# USB3_PHY_RX register map
Vendor: Texas Instruments
Peripheral module from a debugger description file (folder am571x).
Registers are 32-bit, access per field, reset 0x0 unless marked. A register's access mark holds for its fields unless they carry their own. Offsets are as the file gives them; lines under a group give offsets from that group; [hi:lo] are bit positions; {n}, {i} and the like mark numbered series; 'fields as' and 'values as' point back to an identical list; <NAME> marks a mode.

## USB3_PHY_RX
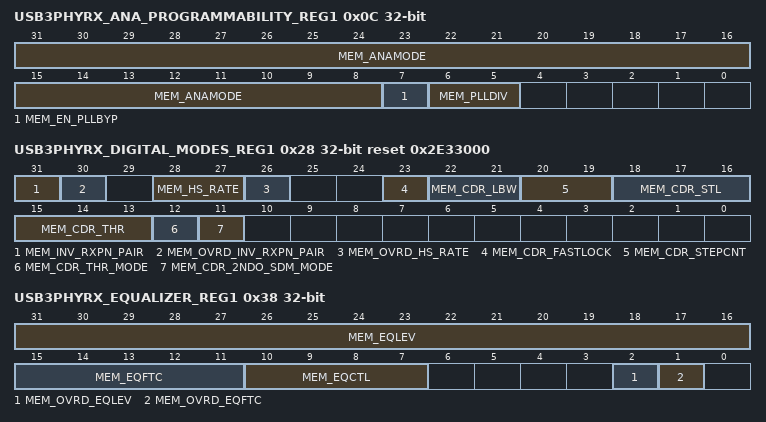
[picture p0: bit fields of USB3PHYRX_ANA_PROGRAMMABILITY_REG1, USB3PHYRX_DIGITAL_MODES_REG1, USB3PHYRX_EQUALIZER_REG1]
0x0C USB3PHYRX_ANA_PROGRAMMABILITY_REG1 — Some programmability for different analog circuits in the PHY.
  [31:8] MEM_ANAMODE rw — Programmability for Analog circuits in the IP. The top 5 bits - MEM_ANAMODE[31:27] indicate the serial Interface using this PHY module. To select USB Super-Speed interface mode, user must set bit MEM_ANAMODE [31] to '0b1', and the other bits must be written to '0b0', as follows: MEM_ANAMODE[31:27] = '0b10000' for the USB Super-Speed. Bits [17:14] of the MEM_ANAMODE bitfield are used to control loss-of-signal detection (LOSD) threshold.
  [7] MEM_EN_PLLBYP rw — 0: USB Mode (uses PLL_CLK input clock)
  [6:5] MEM_PLLDIV rw — This is a test mode. SoC Users are requested to leave this at default value. The input PLL_CLK (after being muxed with PLLBYPCLK) is divided by the following factors indicated by this register. 00=1 01=2 10=4 11=RESERVED. All references to PLL_CLK in this register descriptions are AFTER considering this division.
0x1C USB3PHYRX_TRIM_REG4 rw — The IP requires some values to be remembered in EFUSE. This register provides an alternative to EFUSE.
  [31:30] MEM_DLL_TRIM_SEL — Determines which of the 4 EFUSE registers EFUSE_dll_rateN_coarsetrim should be used as the trim code by the DLL. This feature is so that the user may find and store the trim codes corresponding to different (at most 4) DLL frequencies (PLL_CLK (after the bypassing by MEM_EN_PLLBYP and the division by MEM_PLLDIV) frequencies) and at wake-up, instruct the IP to choose one of these available trim values depending on the Application's frequency requirement. 00 selects dll_rate0_coarsetrim 01 selects dll_rate1_coarsetrim 10 selects dll_rate2_coarsetrim 11 selects dll_rate3_coarsetrim.
0x24 USB3PHYRX_DLL_REG1 reset 0xC0A41915 — This register is used to program DLL settings.
  [31:30] MEM_DLL_PHINT_RATE rw — Programs the DLL and the Phase Interpolator analog circuits to work with different clock frequencies. The frequency of PLL_CLK (after the bypassing by MEM_EN_PLLBYP and the division by MEM_PLLDIV) should be indicated by this register. 00=0.625GHz to 0.75GHz 01=RESERVED 10=1.25GHz to 1.5GHz 11=2.5GHz to 2.9GHz.
0x28 USB3PHYRX_DIGITAL_MODES_REG1 reset 0x2E33000 — This register contains control bits which affect different circuits in digital section of the PHY.
  [31] MEM_INV_RXPN_PAIR rw — If '1', interchanges RXP and RXN effectively by inverting the received data samples.
  [30] MEM_OVRD_INV_RXPN_PAIR rw — Pin override control. See register bit MEM_INV_RXPN_PAIR.
  [28:27] MEM_HS_RATE rw — Determines the ratio of PLL_CLK (after the bypassing by MEM_EN_PLLBYP and the division by MEM_PLLDIV) frequency and the output data rate. Full Rate means PLL_CLK (after the bypassing by MEM_EN_PLLBYP and the division by MEM_PLLDIV) frequency = Data Rate/2 00=Full Rate 01=Half Rate 10=Quarter Rate 11=RESERVED. This takes effect only if register bit MEM_OVRD_HS_RATE is '1', else the same is controlled by input pins hs_rate.
  [26] MEM_OVRD_HS_RATE rw — Pin override control. See register bit MEM_HS_RATE.
  [23] MEM_CDR_FASTLOCK rw — '1' to reduce lock time of CDR (clock-data-recovery circuit).
  [22:21] MEM_CDR_LBW rw — CDR band-width control.
  [20:19] MEM_CDR_STEPCNT rw — CDR 2nd order setting.
  [18:16] MEM_CDR_STL rw — CDR settling time. Determines the number of vote clocks to blank ELV (Early-Late-Voter circuit) after update of phase.
  [15:13] MEM_CDR_THR rw — CDR 1st order threshold. Determines how much early/late votes should differ by before a phase change in the receiver sampling clock is triggered.
  [12] MEM_CDR_THR_MODE rw — CDR 1st order threshold.
  [11] MEM_CDR_2NDO_SDM_MODE rw — If '1', the 2nd Order CDR block uses a 1st order Sigma Delta Modulator to accomplish frequency offset If '0', a simple rate transformer is used for the same purpose.
0x38 USB3PHYRX_EQUALIZER_REG1 — The IP has an Equalizer (with analog and digital parts) which addresses Inter Symbol Interference (ISI). This register is for its controllability. The equalizer can be conﬁgured via the EQCTL bits which are part of the SCP register. The options are: No adaptive equalisation. The equalizer provides a ﬂat response at the maximum gain. This setting may be appropriate if jitter at the receiver occurs predominantly as a result of crosstalk rather than frequency dependent loss. Fully adaptive equalisation. Both the low frequency gain and zero position of the equalizer are determined algorithmically by analysing the data patterns and transition positions in the received data. This setting should be used for most applications. Partially adaptive equalisation. The low frequency gain of the equalizer is determined algorithmically by analysing the data patterns and transition positions in the received data. The zero position is ﬁxed in one of eight zero positions. When enabled, the receiver equalization logic analyzes data patterns and transition times to determine whether the low frequency gain of the equalizer should be increased or decreased. For the fully adaptive setting (EQCTL = 0001), if the low frequency gain reaches the minimum value, the zero frequency is then reduced. Likewise, if it reaches the maximum value, the zero frequency is then increased.
  [31:16] MEM_EQLEV rw — Equalizer level control.
  [15:11] MEM_EQFTC rw — Equalizer zero freq control.
  [10:7] MEM_EQCTL rw — 0000 - Equalizer disabled 0001 - Fully adaptive; FTC normal 0010 - Fully adaptive; FTC inverted 0011 - Hold eq state 01xx - Init eq to fully adaptive start/midpoint 1000 - Partially adaptive; zero=1084 MHz 1001 - Partially adaptive; zero= 805 MHz 1010 - Partially adaptive; zero= 573 MHz 1011 - Partially adaptive; zero= 402 MHZ 1100 - Partially adaptive; zero= 304 MHz 1101 - Partially adaptive; zero= 216 MHz 1110 - Partially adaptive; zero= 156 MHz 1111 - Partially adaptive; zero= 135 MHz
  [2] MEM_OVRD_EQLEV rw — Continuosly forces the Equalizer output with the eqlev[15:0].
  [1] MEM_OVRD_EQFTC rw — Continuosly forces the Equalizer output with the eqftc[4:0].
